# RS1xxxx register map
Vendor: Silicon Lab Inc.; Series: ARMCM4; File version: 1.2
CPU: CM4 r1p0, little endian, MPU, FPU, 6 interrupt priority bits
Registers are 32-bit, read-write, reset 0x0 unless marked. A register's access mark holds for its fields unless they carry their own. Offsets are from the block's base; [hi:lo] are bit positions; lines under a group give offsets from that group; {n}, {i} and the like mark numbered series; 'fields as' and 'values as' point back to an identical list.

## Instruction_Cache_Controller — The Instruction Cache Controller controls the instruction fetching from External Memory into Local Cache for access to the processor.
Base 0x20280000
0x04 RAM_CTRL_REG reset not defined — Rams control register
  [0] Rams_Ownership_of_Second_set — This bit controls the ownership of second set of rams when number of ways is 4 and 32k memory is enabled.
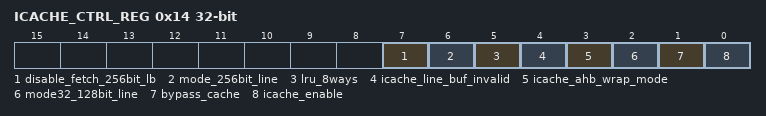
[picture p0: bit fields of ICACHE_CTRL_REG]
0x14 ICACHE_CTRL_REG reset not defined — Icache control register
  [7] disable_fetch_256bit_lb — When set, disables fetching from line buffer which is present in 256-bit mode prefetch module
  [6] mode_256bit_line — selects 1 or 2 128 bit buffer lines used
    0=One 128 bit line buffer is used. Four beat AHB transaction is initiated with the external memory; 1=Two 128 bit line buffers are used. Eight beat AHB transaction is initiated with the external memory
  [5] lru_8ways — Selects whether 8 ways logic is disabled or enabled in controller
    0=Disabled (8 ways logic is disabled in controller); 1=Enabled (8 ways logic is enabled in controller)
  [4] icache_line_buf_invalid — Selects wheter line buffer is valid or invalid
    1=Invalid (line buffer invalid for icc ‘n’); 0=Valid (line buffer valid for icc ‘n’)
  [3] icache_ahb_wrap_mode — Enables or disables wrap mode
    1=Wrap_Enabled (wrap mode is enabled for icc ‘n’); 0=Wrap_Disabled (wrap mode is disabled for icc ‘n’.)
  [2] mode32_128bit_line — selects 128bit or 32 bit for AHB requests, valid only when Cache is disable
    1=32 bit mode is enabled for icc ‘n’. AHB requests will be 32 bit; 0=128 bit mode enabled for icc ‘n’. AHB requests will be 128 bit
  [1] bypass_cache — Tells where fectch requests are served through,valid only when ichache is enable
    1=via_ahb (Fetch Requests are served via ahb, bypassing the cache rams); 0=Through_Icache_Rams (Fetch Requests are served through icache rams)
  [0] icache_enable — Tells if an icache is enables or not for ICC 'n'
    1=ICache_Enabled (Icache is enabled and cache access can take place via ICC ‘n’); 0=Ichache_Not_Enabled (Icache is not enabled for icc ‘n’)
{0x24+4i} ADDR_TRANSLATE_SEGn_CTRL_REG[{i}] (i=0..14) group — Address Translate Value Segment Registers (1-15)
  0x00 ADDR_TRANSLATE_SEG_n1__CTRL_REG reset not defined — Address Translate Value Segment Register__n1_
    [31:21] Segment_Address_Value

## MCU_ULP_VBAT_CLOCK_ARCHITECTURE — clock select registers for the ULP VBAT peripherals
Base 0x24048000
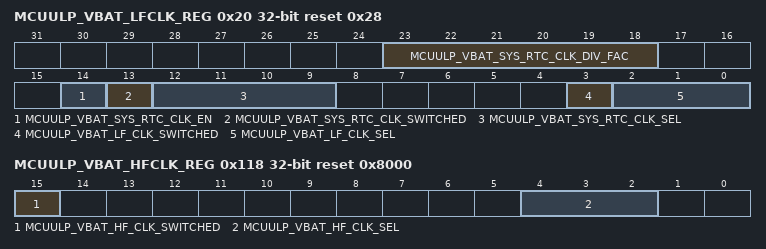
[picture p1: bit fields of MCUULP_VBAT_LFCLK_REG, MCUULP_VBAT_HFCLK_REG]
0x20 MCUULP_VBAT_LFCLK_REG reset 0x28 — Low frequency clock select register
  [23:18] MCUULP_VBAT_SYS_RTC_CLK_DIV_FAC — Division factor for RC_32_MHZ_CLK
  [14] MCUULP_VBAT_SYS_RTC_CLK_EN — Writing 1 to this enables clock to SYSRTC from dynamic mux.Writing 0 to this has no effect.
  [13] MCUULP_VBAT_SYS_RTC_CLK_SWITCHED ro — Status of Dynamic Clock Mux in Reference Clock Generation
  [12:9] MCUULP_VBAT_SYS_RTC_CLK_SEL — mcuulp vbat sysrtc clock select
  [3] MCUULP_VBAT_LF_CLK_SWITCHED ro — Status of NPSS Low Frequency Clock Dynamic Clock Mux
  [2:0] MCUULP_VBAT_LF_CLK_SEL — mcuulp vbat low frequecy clock select
0x118 MCUULP_VBAT_HFCLK_REG reset 0x8000 — High frequency clock select register
  [15] MCUULP_VBAT_HF_CLK_SWITCHED ro — Status of NPSS High Frequency Clock Dynamic Clock Mux
  [4:2] MCUULP_VBAT_HF_CLK_SEL — mcuulp high frequency clock select

## MCU_ULP_CLOCK_OSCILLATORS — ULP Clock Oscillators Control Registers
Base 0x24048100
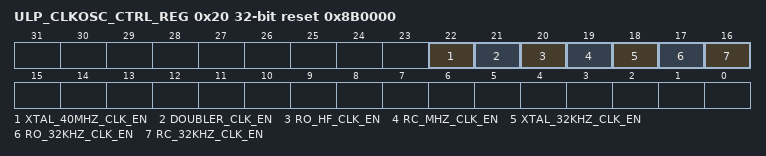
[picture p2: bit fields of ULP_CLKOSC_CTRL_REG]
0x20 ULP_CLKOSC_CTRL_REG reset 0x8B0000 — ULP Clock Oscillators Control Registers
  [22] XTAL_40MHZ_CLK_EN — 1-Enable XTAL 40MHz clock, 0-disable XTAL 40 MHz clock
    1=Enable XTAL 40MHz clock; 0=Disable XTAL 40MHz clock
  [21] DOUBLER_CLK_EN — 1-Enable Doubler clock, 0-disable Doubler clock
    1=Enable Doubler clock; 0=Disable Doubler clock
  [20] RO_HF_CLK_EN — 1-Enable RO High Frequency clock, 0-disable RO High Frequency clock
    1=Enable RC 32Mhz clock; 0=Disable RC 32Mhz clock
  [19] RC_MHZ_CLK_EN — 1-Enable RC 32Mhz clock, 0-disable RC 32 Mhz clock
    1=Enable RC 32Mhz clock; 0=Disable RC 32Mhz clock
  [18] XTAL_32KHZ_CLK_EN — 1-Enable XTAL 32khz clock, 0-disable XTAL 32 khz clock
    1=Enable XTAL 32khz clock; 0=Disable XTAL 32khz clock
  [17] RO_32KHZ_CLK_EN — 1-Enable RO 32khz clock, 0-disable RO 32 khz clock
    1=Enable RO 32khz clock; 0=Disable RO 32khz clock
  [16] RC_32KHZ_CLK_EN — 1-Enable RC 32khz clock, 0-disable RC 32 khz clock
    1=Enable RC 32khz clock; 0=Disable RC 32khz clock

## MCU_MULTI_CHANNEL_INTERRUPT_SELECT — MCU Multi channel interrupt select registers
Base 0x46110000
0x04 M4SS_GPDMA_INTR_SEL — MCU GPDMA interrupt selection register
  [7:0] dma_m_interrupt_sel — This bit unmasks m th the GPDMA channel interrupt
    1=UNMASKED (Interrupt is not masked); 0=MASKED (Interrupt is masked)
0x0C M4SS_UDMA_INTR_SEL — MCU HP uDMA interrupt selection register
  [31:0] udma_m_interrupt_sel — This bit unmasks the m th UDMA channel interrupt
    values as M4SS_GPDMA_INTR_SEL.dma_m_interrupt_sel
0x10 M4SS_SCT_INTR_SEL — SCT interrupt selection register
  [31:0] sct_m_interrupt_sel — This bit unmasks the m th SCT channel interrupt
    values as M4SS_GPDMA_INTR_SEL.dma_m_interrupt_sel
